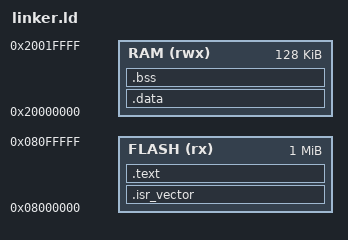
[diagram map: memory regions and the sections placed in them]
ENTRY(Reset_Handler)

/*
 * STM32F429IGT6
 * Internal Flash: 1 MiB at 0x08000000
 * Main system SRAM used here: 128 KiB at 0x20000000
 *
 * The separate CCM RAM is deliberately not used in this first experiment.
 */
MEMORY
{
    FLASH (rx)  : ORIGIN = 0x08000000, LENGTH = 1024K
    RAM   (rwx) : ORIGIN = 0x20000000, LENGTH = 128K
}

_estack = ORIGIN(RAM) + LENGTH(RAM);

SECTIONS
{
    .isr_vector :
    {
        . = ALIGN(4);
        KEEP(*(.isr_vector))
        . = ALIGN(4);
    } > FLASH

    .text :
    {
        . = ALIGN(4);
        *(.text*)
        *(.rodata*)
        . = ALIGN(4);
        _etext = .;
    } > FLASH

    .data : AT(_etext)
    {
        . = ALIGN(4);
        _sdata = .;
        *(.data*)
        . = ALIGN(4);
        _edata = .;
    } > RAM

    .bss (NOLOAD) :
    {
        . = ALIGN(4);
        _sbss = .;
        *(.bss*)
        *(COMMON)
        . = ALIGN(4);
        _ebss = .;
    } > RAM

    . = ALIGN(8);
    _end = .;
}
